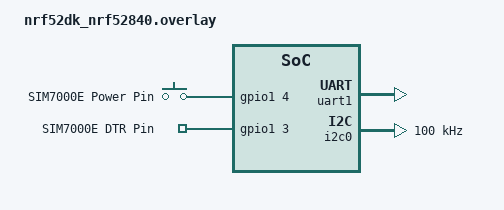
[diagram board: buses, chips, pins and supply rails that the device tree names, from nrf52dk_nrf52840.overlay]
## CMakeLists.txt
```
cmake_minimum_required(VERSION 3.20.0)
find_package(Zephyr REQUIRED HINTS $ENV{ZEPHYR_BASE})

project(nb-iot)

target_include_directories(app PRIVATE "include")

target_sources(app PRIVATE 
    "include/at/prv.hpp"
    "include/at/sim7000e/https.hpp"
    "include/at/sim7000e/power.hpp"
    "include/at/sim7000e/network_configuration.hpp"
    "include/at/sim7000e/time.hpp"
    "include/at/common.hpp"
    "include/uart/uart.hpp"
    "include/gpio/gpio.hpp"
    "include/iic/time.hpp"
    "include/iic/bus.hpp"

    "src/iic/time.cpp"
    "src/iic/bus.cpp"
    "src/at/prv.cpp"
    "src/at/sim7000e/https.cpp"
    "src/at/sim7000e/power.cpp"
    "src/at/sim7000e/network_configuration.cpp"
    "src/at/sim7000e/time.cpp"
    "src/uart/uart.cpp"
    "src/gpio/gpio.cpp"
    "src/main.cpp"
    )
```

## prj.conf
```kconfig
# configure language supprot and functions
CONFIG_CPP=y
CONFIG_REQUIRES_FULL_LIBCPP=y
CONFIG_STD_CPP20=y
CONFIG_REQUIRES_FULL_LIBC=y

CONFIG_SERIAL=y

# configuring uart
CONFIG_UART_INTERRUPT_DRIVEN=y
CONFIG_UART_USE_RUNTIME_CONFIGURE=y

# enable uart for measuring power consumption and waking modules up
CONFIG_GPIO=y
CONFIG_PM_DEVICE=y=y

# enable i2c for communication with real time clock
CONFIG_I2C=y

# we enable poll for working with uart
# this allows for efficient use of message queues
CONFIG_POLL=y

# configure the default stack size
# wee store most data on the stack
CONFIG_MAIN_STACK_SIZE=4096

# configure available time functions
CONFIG_POSIX_CLOCK=y

# configure logging via rtt
CONFIG_LOG=y
CONFIG_LOG_BACKEND_RTT=y
CONFIG_LOG_MODE_DEFERRED=y
CONFIG_LOG_PRINTK=y
CONFIG_USE_SEGGER_RTT=y
```

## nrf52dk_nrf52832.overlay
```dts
&uart0{
    status = "okay";
    pinctrl-0 = <&uart0_default>;
    pinctrl-1 = <&uart0_sleep>;
    pinctrl-names = "default", "sleep";
    // sim7000 {
    //   compatible = "simcom,sim7000";
    //   status = "okay";
    //   pin-dtr = <&gpio0 13 (GPIO_PULL_DOWN | GPIO_ACTIVE_HIGH)>;
    //   pin-power = <&gpio0 15 (GPIO_ACTIVE_HIGH)>;
    //   current-speed = <115200>;
    // };
};

&gpio0 {
    status = "okay";
};

&uart0_default {
  group1 {
    psels = <NRF_PSEL(UART_TX, 0, 3)>,
      <NRF_PSEL(UART_RX, 0, 4)>,
      <NRF_PSEL(UART_RTS, 0, 5)>,
      <NRF_PSEL(UART_CTS, 0, 7)>;
  };
};

// &pinctrl {
//   uart0_sim7000e: uart0_sim7000e {
//     group1 {
//       psels = <NRF_PSEL(UART_TX, 0, 6)>,
//         <NRF_PSEL(UART_RX, 0, 8)>,
//         <NRF_PSEL(UART_RTS, 0, 5)>,
//         <NRF_PSEL(UART_CTS, 0, 7)>;
//     };
//   };
// };
&clock {
    status = "okay";
};
```

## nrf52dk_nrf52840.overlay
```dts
&uart1 {
    status = "okay";
    pinctrl-0 = <&uart1_default>;
    pinctrl-1 = <&uart1_sleep>;
    wakeup-source;
};

&gpio0 {
    status = "okay";
};


&i2c0 {
    compatible = "nordic,nrf-twim";
    clock-frequency = <100000>;
    status = "okay";
};
/{
    custom_gpios {

        compatible = "gpio-keys";

        sim7000e_power: sim7000e_0 {
            gpios = <&gpio1 4 GPIO_ACTIVE_HIGH>;
            label = "SIM7000E Power Pin";
        };

        sim7000e_dtr: sim7000e_1 {
            gpios = <&gpio1 3 GPIO_ACTIVE_HIGH>;
            label = "SIM7000E DTR Pin";
        };

    };

    aliases {
        sim7000epower = &sim7000e_power;
        sim7000edtr = &sim7000e_dtr;
    };
};
```

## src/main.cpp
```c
#include <zephyr/kernel.h>
#include <zephyr/logging/log.h>
#include <fcntl.h>
#include <unistd.h>
// uart
#include "uart/uart.hpp"
// gpio
#include "gpio/gpio.hpp"
// sim7000e
#include "at/sim7000e/https.hpp"
#include "at/sim7000e/time.hpp"
#include "at/sim7000e/network_configuration.hpp"
#include "at/sim7000e/power.hpp"
// iic
#include "iic/bus.hpp"
#include "iic/time.hpp"

LOG_MODULE_REGISTER(main);

int main_send_mb_iot_msg()
{

    if (uart::uart_init() != 0)
    {
        LOG_ERR("UART initialization failed\n");
        return -1;
    }

    if (iic::bus::setup() != 0)
    {
        LOG_ERR("I2C bus setup failed");
        return -1;
    }

    if (gpio::init() != gpio::OK)
    {
        LOG_ERR("GPIO initialization failed");
        return -1;
    }

    if (gpio::set(gpio::SIM7000_PWR, gpio::HIGH) != gpio::OK)
    {
        LOG_ERR("SIM7000E power on failed");
        return -1;
    }

    // k_sleep(K_MSEC(5000));

    while (at::commands::sim7000e::https::check_sim7000e_present() != at::commands::OK)
    {
        LOG_ERR("SIM7000E not responding");
    }

    at::commands::sim7000e::https::reboot();

    while (at::commands::sim7000e::https::check_sim7000e_present() != at::commands::OK)
    {
        LOG_ERR("SIM7000E not responding");
    }

    bool ip_not_available = false;
    std::string ip;
    // if (at::commands::sim7000e::https::get_ip(ip) != at::commands::OK)
    // {
    //     LOG_ERR("SIM7000E IP address retrieval failed");
    //     ip_not_available = true;
    // }

    ip_not_available = ip_not_available || ip.empty() || ip == "0.0.0.0";

    while (ip_not_available && at::commands::sim7000e::network_configuration::setup_apn("internet") != at::commands::OK)
    {
        LOG_ERR("SIM7000E APN setup failed");
    }

    if (ip_not_available)
    {
        if (at::commands::sim7000e::network_configuration::get_ip(ip) != at::commands::OK)
        {
            LOG_ERR("SIM7000E IP address retrieval failed");
        }
        else
        {
            LOG_INF("IP address: %s", ip.c_str());
        }
    }
    if (at::commands::sim7000e::https::ignore_ssl_timestamp() != at::commands::OK)
    {
        LOG_ERR("SIM7000E SSL timestamp ignore failed");
    }

    if (at::commands::sim7000e::https::set_ssl_version() != at::commands::OK)
    {
        LOG_ERR("SIM7000E SSL version set failed");
    }

    if (at::commands::sim7000e::https::set_server_name_indication("static.woyte.dev") != at::commands::OK)
    {
        LOG_ERR("SIM7000E server name indication set failed");
    }

    if (at::commands::sim7000e::https::trust_all_certificates() != at::commands::OK)
    {
        LOG_ERR("SIM7000E trust all certificates failed");
        return -1;
    }

    struct tm time = iic::time::get_current_time();

    std::string body = "{";
    body += "\"time\": \"";
    // body += "2021-09-01T12:00:00+00:00\","; // current time in ISO 8601 format
    body += ((time.tm_year + 1900) < 9 ? "0" : "") + std::to_string(time.tm_year + 1900) + "-";
    body += (time.tm_mon + 1 < 9 ? "0" : "") + std::to_string(time.tm_mon + 1) + "-";
    body += (time.tm_mday < 9 ? "0" : "") + std::to_string(time.tm_mday) + "T";
    body += (time.tm_hour < 9 ? "0" : "") + std::to_string(time.tm_hour) + ":";
    body += (time.tm_min < 9 ? "0" : "") + std::to_string(time.tm_min) + ":";
    body += (time.tm_sec < 9 ? "0" : "") + std::to_string(time.tm_sec) + "+00:00" + "\",";
    body += "\"temperature\": 25.5,";
    body += "\"humidity\": 50.5";
    body += "}";

    // set_body_length
    if (at::commands::sim7000e::https::set_body_length(1024) != at::commands::OK)
    {
        LOG_ERR("SIM7000E body length set failed");
        return -1;
    }

    // set_header_length
    if (at::commands::sim7000e::https::set_header_length(350) != at::commands::OK)
    {
        LOG_ERR("SIM7000E header length set failed");
        return -1;
    }

    // set domain for Server Name Indication
    if (at::commands::sim7000e::https::set_domain("https://static.woyte.dev") != at::commands::OK)
    {
        LOG_ERR("SIM7000E domain set failed");
        return -1;
    }

    std::string time_request = "";

    if (at::commands::sim7000e::time::get_time(time_request) != at::commands::OK)
    {
        LOG_ERR("SIM7000E time get failed");
    }

    if (time_request.find("+CCLK: \"80") != std::string::npos)
    {
        LOG_INF("Need to set time");
        // set_time
        if (at::commands::sim7000e::time::set_time() != at::commands::OK)
        {
            LOG_ERR("SIM7000E time set failed");
            return -1;
        }
    }

    // start_ssl_session
    at::commands::result sslstartresult = at::commands::sim7000e::https::start_ssl_session();
    if (sslstartresult != at::commands::OK)
    {
        LOG_ERR("SIM7000E SSL session start failed");
        LOG_ERR("REASON: %d", sslstartresult);
        // return;
    }

    // // start_header
    // if (at::commands::sim7000e::https::start_header() != at::commands::OK)
    // {
    //     LOG_ERR("SIM7000E header start failed");
    //     return -1;
    // }

    // clear header
    if (at::commands::sim7000e::https::clear_header() != at::commands::OK)
    {
        LOG_ERR("SIM7000E header clear failed");
        return -1;
    }

    // set_header
    if (at::commands::sim7000e::https::set_header("Content-Type", "application/json") != at::commands::OK)
    {
        LOG_ERR("SIM7000E header set failed");
        return -1;
    }

    // AT+SHAHEAD="User-Agent","curl/7.47.0"
    if (at::commands::sim7000e::https::set_header("User-Agent", "curl/7.47.0") != at::commands::OK)
    {
        LOG_ERR("SIM7000E header user-agent set failed");
        return -1;
    }

    // AT+SHAHEAD="Cache-control","no-cache"
    if (at::commands::sim7000e::https::set_header("Cache-control", "no-cache") != at::commands::OK)
    {
        LOG_ERR("SIM7000E header cache control set failed");
        return -1;
    }

    // AT+SHAHEAD="Accept","*/*"
    if (at::commands::sim7000e::https::set_header("Accept", "*/*") != at::commands::OK)
    {
        LOG_ERR("SIM7000E header accept set failed");
        return -1;
    }

    // set_body
    if (at::commands::sim7000e::https::set_body(body) != at::commands::OK)
    {
        LOG_ERR("SIM7000E body set failed");
        return -1;
    }

    int http_status_code;
    int length;
    if (at::commands::sim7000e::https::exec("/api/save_to_db", at::commands::sim7000e::https::http_method::POST, http_status_code, length) != at::commands::OK)
    {
        LOG_ERR("SIM7000E exec failed");
        return -1;
    }

    LOG_INF("HTTP status code: %d", http_status_code);
    LOG_INF("Length: %d", length);

    // read response
    std::string response;
    if (at::commands::sim7000e::https::read(response, length) != at::commands::OK)
    {
        LOG_ERR("SIM7000E read failed");
        return -1;
    }

    LOG_INF("Response: %s", response.c_str());

    if (at::commands::sim7000e::https::stop_ssl_session() != at::commands::OK)
    {
        LOG_ERR("SIM7000E SSL session stop failed");
        return -1;
    }

    // if (at::commands::sim7000e::network_configuration::network_disconnect() != at::commands::OK)
    // {
    //     LOG_ERR("SIM7000E network disconnect failed");
    //     return -1;
    // }

    return 0;
}

int send_to_sleep()
{
    // power off the module

    // Enable PSM event reporting
    if (at::commands::sim7000e::power::set_psm_event_report(at::commands::sim7000e::power::PSM_EVENT_REPORT_ENABLE) != at::commands::OK)
    {
        LOG_ERR("SIM7000E PSM event report enable failed");
        return -1;
    }
    // fix baud rate
    if (at::commands::sim7000e::power::fix_baud_rate() != at::commands::OK)
    {
        LOG_ERR("SIM7000E fix baud rate failed");
        return -1;
    }

    // enable slow clock
    if (at::commands::sim7000e::power::set_slow_clock(true) != at::commands::OK)
    {
        LOG_ERR("SIM7000E enable slow clock failed");
        return -1;
    }

    // disconnect from networt to enter PSM
    if (at::commands::sim7000e::network_configuration::network_disconnect() != at::commands::OK)
    {
        LOG_ERR("SIM7000E network disconnect failed");
    }

    if (at::commands::sim7000e::power::enter_idle_mode() != at::commands::OK)
    {
        LOG_ERR("SIM7000E enter idle mode failed");
        return -1;
    }

    // Inquiry timers configured by network. (optional)
    // Enable PSM mode and set the specific T3412_ext and T3324
    if (at::commands::sim7000e::power::enable_PSM() != at::commands::OK)
    {
        LOG_ERR("SIM7000E enable PSM failed");
        return -1;
    }

    // wait for wait_for_enter_psm
    if (at::commands::sim7000e::power::wait_for_enter_psm() != at::commands::OK)
    {
        LOG_ERR("SIM7000E wait for enter PSM failed");
        // k_sleep(K_MSEC(1000));
    }
    else
    {
        LOG_INF("Entering PSM successfully");
    }

    // wait for wait_for_exit_psm
    if (at::commands::sim7000e::power::wait_for_exit_psm() != at::commands::OK)
    {
        LOG_ERR("SIM7000E wait for exit PSM failed");
    }
    else
    {
        LOG_INF("Exited PSM successfull");
    }

    // disable slow clock
    if (at::commands::sim7000e::power::set_slow_clock(false) != at::commands::OK)
    {
        LOG_ERR("SIM7000E disable slow clock failed");
        return -1;
    }

    k_sleep(K_MSEC(10000));
    return 0;
}

int main_send_to_sleep()
{
    if (uart::uart_init() != 0)
    {
        LOG_ERR("UART initialization failed");
        return -1;
    }

    if (gpio::init() != gpio::OK)
    {
        LOG_ERR("GPIO initialization failed");
        return -1;
    }

    // module powers on by default when recieving power for the first time
    // we set it to low to power on the module from deep sleep
    if (gpio::set(gpio::SIM7000_PWR, gpio::LOW) != gpio::OK)
    {
        LOG_ERR("SIM7000E GPIO power set failed");
        return -1;
    }

    if (iic::bus::setup() != 0)
    {
        LOG_ERR("I2C bus setup failed");
        return -1;
    }

    // gpio::gpio_state state = gpio::LOW;

    // for (size_t i = 0; i < 10; i++)
    // {
    //     if(gpio::set(gpio::SIM7000_PWR, state))
    //     {
    //         LOG_ERR("SIM7000E GPIO power set failed");
    //         return -1;
    //     }
    //     k_sleep(K_MSEC(1000));
    //     state = state == gpio::LOW ? gpio::HIGH : gpio::LOW;
    // }

    if (at::commands::sim7000e::https::check_sim7000e_present() != at::commands::OK)
    {
        LOG_INF("SIM7000E not responding");

        // power on the module
        if (gpio::set(gpio::SIM7000_PWR, gpio::HIGH) != gpio::OK)
        {
            return -1;
        }

        k_sleep(K_MSEC(100));

        // wait for the module to boot
        while (at::commands::sim7000e::https::check_sim7000e_present() != at::commands::OK)
        {
            LOG_INF("SIM7000E not responding");
            k_sleep(K_MSEC(1000));
        }
    }

    while (1)
    {
        bool ip_not_available = false;
        std::string ip;
        if (at::commands::sim7000e::network_configuration::get_ip(ip) != at::commands::OK)
        {
            LOG_ERR("SIM7000E IP address retrieval failed");
            ip_not_available = true;
        }

        ip_not_available = ip_not_available || ip.empty() || ip == "0.0.0.0";

        while (ip_not_available && at::commands::sim7000e::network_configuration::setup_apn("internet") != at::commands::OK)
        {
            LOG_ERR("SIM7000E APN setup failed");
            k_sleep(K_MSEC(1000));
        }

        if (ip_not_available)
        {
            if (at::commands::sim7000e::network_configuration::get_ip(ip) != at::commands::OK)
            {
                LOG_ERR("SIM7000E IP address retrieval failed");
            }
            else
            {
                LOG_INF("IP address: %s", ip.c_str());
            }
        }

        return 0;
    }
    send_to_sleep();
}

int main_power_off()
{
    if (uart::uart_init() != 0)
    {
        LOG_ERR("UART initialization failed");
        return -1;
    }

    if (gpio::init() != gpio::OK)
    {
        LOG_ERR("GPIO initialization failed");
        return -1;
    }

    // POWER THE MODULE
    // we set it to low to power on the module from deep sleep
    if (gpio::set(gpio::SIM7000_PWR, gpio::LOW) != gpio::OK)
    {
        LOG_ERR("SIM7000E GPIO power set failed");
        return -1;
    }

    if (iic::bus::setup() != 0)
    {
        LOG_ERR("I2C bus setup failed");
        return -1;
    }

    if (at::commands::sim7000e::https::check_sim7000e_present() != at::commands::OK)
    {
        LOG_INF("SIM7000E not responding");

        // power on the module
        if (gpio::set(gpio::SIM7000_PWR, gpio::HIGH) != gpio::OK)
        {
            return -1;
        }

        k_sleep(K_MSEC(100));

        // wait for the module to boot
        while (at::commands::sim7000e::https::check_sim7000e_present() != at::commands::OK)
        {
            LOG_INF("SIM7000E not responding");
        }
    }
    bool ip_not_available = false;
    std::string ip;
    if (at::commands::sim7000e::network_configuration::get_ip(ip) != at::commands::OK)
    {
        LOG_ERR("SIM7000E IP address retrieval failed");
        ip_not_available = true;
    }

    ip_not_available = ip_not_available || ip.empty() || ip == "0.0.0.0";

    while (ip_not_available && at::commands::sim7000e::network_configuration::setup_apn("internet") != at::commands::OK)
    {
        LOG_ERR("SIM7000E APN setup failed");
        k_sleep(K_MSEC(1000));
    }

    if (ip_not_available)
    {
        if (at::commands::sim7000e::network_configuration::get_ip(ip) != at::commands::OK)
        {
            LOG_ERR("SIM7000E IP address retrieval failed");
        }
        else
        {
            LOG_INF("IP address: %s", ip.c_str());
        }
    }

    // power off the module
    if (at::commands::sim7000e::power::power_off(false) != at::commands::OK)
    {
        LOG_ERR("SIM7000E power off failed");
        return -1;
    }

    LOG_INF("SIM7000E powered off");
    gpio::set(gpio::SIM7000_PWR, gpio::LOW);

    // k_sleep(K_MSEC(10000));

    // LOG_INF("SIM7000E power on");
    // at::commands::result present_check_result = at::commands::sim7000e::https::check_sim7000e_present();
    // if (present_check_result != at::commands::TIMEOUT)
    // {
    //     LOG_INF("SIM7000E not responding");
    // }
    // else if (present_check_result == at::commands::OK)
    // {
    //     LOG_ERR("SIM7000E is responding");
    // }

    // // power on the module
    // if (gpio::set(gpio::SIM7000_PWR, gpio::LOW) != gpio::OK)
    // {
    //     return -1;
    // }

    // // while (at::commands::sim7000e::https::check_sim7000e_present() != at::commands::OK)
    // // {
    // //     LOG_INF("SIM7000E not responding");
    // //     k_sleep(K_MSEC(1000));
    // // }

    // if (at::commands::sim7000e::power::wait_for_boot() != at::commands::OK)
    // {
    //     LOG_ERR("SIM7000E wait for boot failed");
    //     return -1;
    // }

    // LOG_INF("SIM7000E powered on and ready");

    while (1)
    {
        k_sleep(K_MSEC(1000));
    }
    return 0;
}

int main(void)
{
    main_send_mb_iot_msg();
    // power off the module
    if (at::commands::sim7000e::power::power_off(false) != at::commands::OK)
    {
        LOG_ERR("SIM7000E power off failed");
        return -1;
    }

    gpio::set(gpio::SIM7000_PWR, gpio::LOW);

    while (1)
    {
        uart::read_result uart_res;
        std::string response = "";
        uart_res = uart::uart_read(response);
        if (uart_res == uart::read_result::UART_READ_OK)
        {
            LOG_INF("Response: %s", response.c_str());
        }
        if (uart_res == uart::read_result::UART_READ_ERROR)
        {
            LOG_ERR("UART read error");
        }
    }

    return 0;
}
```

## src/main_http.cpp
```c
#include <zephyr/kernel.h>
#include <zephyr/logging/log.h>
#include <fcntl.h>
#include <unistd.h>
#include <zephyr/drivers/uart.h>
#include <zephyr/device.h>
#include <algorithm>
#include <stdio.h>
#include "uart/uart.hpp"
#include "at/http.hpp"

LOG_MODULE_REGISTER(main);

int main(void)
{
    if (uart::uart_init() != 0)
    {
        printk("UART initialization failed\n");
        return -1;
    }
    // struct k_poll_event events[1];
    // k_poll_event_init(&events[0],
    //                   K_POLL_TYPE_MSGQ_DATA_AVAILABLE,
    //                   K_POLL_MODE_NOTIFY_ONLY,
    //                   &uart::uart_msgq_rx);

    if (at::commands::sim7000e::http::check_sim7000e_present() != at::commands::OK)
    {
        LOG_ERR("SIM7000E not responding\n");
    }

    // if (at::commands::sim7000e::set_network_mode_nb_iot() != at::commands::OK)
    // {
    //     LOG_ERR("Failed to set module to NB-IoT mode\n");
    // }

    if (at::commands::sim7000e::http::enable_scrambling() != at::commands::OK)
    {
        LOG_ERR("Failed to enable scrambling\n");
    }

    std::string provider = "";
    if (at::commands::sim7000e::http::get_operator(provider) != at::commands::OK)
    {
        LOG_ERR("Failed to get operator\n");
    }

    LOG_INF("Operator: %s", provider.c_str());

    if (at::commands::sim7000e::http::configure_bearer_profile() != at::commands::OK)
    {
        LOG_ERR("Failed to configure bearer profile\n");
    }


    if (at::commands::sim7000e::http::enable_bearer_profile() != at::commands::OK)
    {
        LOG_ERR("Failed to enable bearer profile\n");
    }

    std::string ip_address = "";
    if (at::commands::sim7000e::http::get_ip_address(ip_address) != at::commands::OK)
    {
        LOG_ERR("Failed to get IP address\n");
    }

    k_sleep(K_MSEC(1000));
    uart::flush();

    if (at::commands::sim7000e::http::start_http_session() != at::commands::OK)
    {
        LOG_ERR("Failed to start HTTP session\n");
    }

    if (at::commands::sim7000e::http::set_context_id_1() != at::commands::OK)
    {
        LOG_ERR("Failed to set context ID 1\n");
    }

    if (at::commands::sim7000e::http::allow_redirects() != at::commands::OK)
    {
        LOG_ERR("Failed to allow redirects\n");
    }

    if (at::commands::sim7000e::http::set_url("http:/teststaticfunction.azurewebsites.net") != at::commands::OK)
    {
        LOG_ERR("Failed to set URL\n");
    }

    if (at::commands::sim7000e::http::set_content_type("application/json") != at::commands::OK)
    {
        LOG_ERR("Failed to set content type\n");
    }

    if (at::commands::sim7000e::http::add_body("{\"temp\":24}") != at::commands::OK)
    {
        LOG_ERR("Failed to add body\n");
    }

    uart::flush();

    k_sleep(K_MSEC(1000));

    uart::flush();

    int http_status_code;

    if (at::commands::sim7000e::http::exec_post(http_status_code) != at::commands::OK)
    {
        LOG_ERR("Failed to execute POST\n");
    }

    uart::flush();

    k_sleep(K_MSEC(1000));

    uart::flush();

    if (at::commands::sim7000e::http::stop_http_session() != at::commands::OK)
    {
        LOG_ERR("Failed to stop HTTP session\n");
    }  
      uart::flush();

    k_sleep(K_MSEC(1000));

    uart::flush();

    if (at::commands::sim7000e::http::stop_baeer_profile() != at::commands::OK)
    {
        LOG_ERR("Failed to stop bearer profile\n");
    }

    while (1)
    {
        k_sleep(K_MSEC(1000));
    }
}
```

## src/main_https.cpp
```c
#include <zephyr/kernel.h>
#include <zephyr/logging/log.h>
#include <fcntl.h>
#include <unistd.h>
#include <zephyr/drivers/uart.h>
#include <zephyr/device.h>
#include <algorithm>
#include <stdio.h>
#include "uart/uart.hpp"
#include "at/https.hpp"

LOG_MODULE_REGISTER(main);

int main(void)
{
    if (uart::uart_init() != 0)
    {
        printk("UART initialization failed\n");
        return -1;
    }

    while (at::commands::sim7000e::https::check_sim7000e_present() != at::commands::OK)
    {
        LOG_ERR("SIM7000E not responding\n");
    }


    if (at::commands::sim7000e::https::setup_apn("internet") != at::commands::OK)
    {
        LOG_ERR("SIM7000E APN setup failed\n");
    }

    std::string ip;
    if (at::commands::sim7000e::https::get_ip(ip) != at::commands::OK)
    {
        LOG_ERR("SIM7000E IP address retrieval failed\n");
    }
    else
    {
        LOG_INF("IP address: %s", ip.c_str());
    }

    if (at::commands::sim7000e::https::ignore_ssl_timestamp() != at::commands::OK)  {
        LOG_ERR("SIM7000E SSL timestamp ignore failed\n");
    }

    if (at::commands::sim7000e::https::set_ssl_version() != at::commands::OK)  {
        LOG_ERR("SIM7000E SSL version set failed\n");
    }
    

    if (at::commands::sim7000e::https::set_server_name_indication("static.woyte.dev") != at::commands::OK)  {
        LOG_ERR("SIM7000E server name indication set failed\n");
    }

    if (at::commands::sim7000e::https::trust_all_certificates() != at::commands::OK)  {
        LOG_ERR("SIM7000E trust all certificates failed\n");
    }

    std::string body = at::commands::sim7000e::https::escape_body("{\"key\":\"value\"}");

    // set_body_length
    if (at::commands::sim7000e::https::set_body_length(1024) != at::commands::OK)  {
        LOG_ERR("SIM7000E body length set failed\n");
    }

    // set_header_length
    if (at::commands::sim7000e::https::set_header_length(350) != at::commands::OK)  {
        LOG_ERR("SIM7000E header length set failed\n");
    }

    // set_domain
    if (at::commands::sim7000e::https::set_domain("https://static.woyte.dev") != at::commands::OK)  {
        LOG_ERR("SIM7000E domain set failed\n");
    }

    // start_ssl_session
    if (at::commands::sim7000e::https::start_ssl_session() != at::commands::OK)  {
        LOG_ERR("SIM7000E SSL session start failed\n");
    }

    // clear header
    if (at::commands::sim7000e::https::clear_header() != at::commands::OK)  {
        LOG_ERR("SIM7000E header clear failed\n");
    }

    // set_header
    if (at::commands::sim7000e::https::set_header("Content-Type", "application/json") != at::commands::OK)  {
        LOG_ERR("SIM7000E header set failed\n");
    }

    // AT+SHAHEAD="User-Agent","curl/7.47.0"
    if (at::commands::sim7000e::https::set_header("User-Agent", "curl/7.47.0") != at::commands::OK)  {
        LOG_ERR("SIM7000E header set failed\n");
    }

    // AT+SHAHEAD="Cache-control","no-cache"
    if (at::commands::sim7000e::https::set_header("Cache-control", "no-cache") != at::commands::OK)  {
        LOG_ERR("SIM7000E header set failed\n");
    }

    // AT+SHAHEAD="Accept","*/*"
    if (at::commands::sim7000e::https::set_header("Accept", "*/*") != at::commands::OK)  {
        LOG_ERR("SIM7000E header set failed\n");
    }

    // set_body
    if (at::commands::sim7000e::https::set_body(body) != at::commands::OK)  {
        LOG_ERR("SIM7000E body set failed\n");
    }

    int http_status_code;
    int length;
    if (at::commands::sim7000e::https::exec("/api/save_to_db", at::commands::sim7000e::https::http_method::POST, http_status_code, length) != at::commands::OK)  {
        LOG_ERR("SIM7000E exec failed\n");
    }

    LOG_INF("HTTP status code: %d", http_status_code);
    LOG_INF("Length: %d", length);

    // read response
    std::string response;
    if (at::commands::sim7000e::https::read(response, length) != at::commands::OK)  {
        LOG_ERR("SIM7000E read failed\n");
    }

    LOG_INF("Response: %s", response.c_str());

    if (at::commands::sim7000e::https::stop_ssl_session() != at::commands::OK)  {
        LOG_ERR("SIM7000E SSL session stop failed\n");
    }

    if (at::commands::sim7000e::https::network_disconnect() != at::commands::OK)  {
        LOG_ERR("SIM7000E network disconnect failed\n");
    }
}
```
